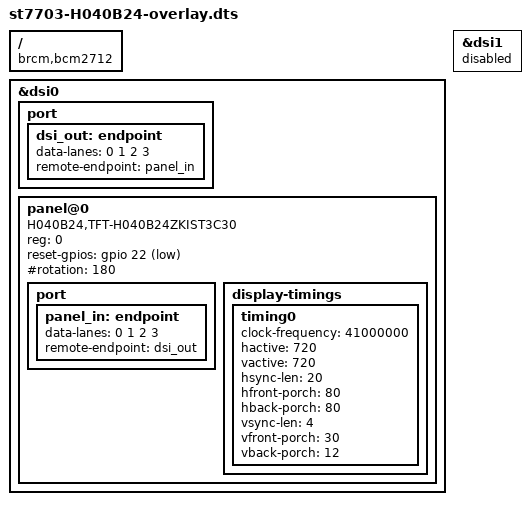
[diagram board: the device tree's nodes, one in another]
/dts-v1/;
/plugin/;

/ {
    compatible = "brcm,bcm2712";
};

&dsi0 {
    status = "okay";
    #address-cells = <1>;
    #size-cells = <0>;

    port {
        dsi_out: endpoint {
            data-lanes = <0 1 2 3>;
            remote-endpoint = <&panel_in>;
        };
    };

    panel@0 {
        compatible = "H040B24,TFT-H040B24ZKIST3C30";
        reg = <0>;
        reset-gpios = <&gpio 22 1>;  /* Active low reset - using GPIO 22 */
        
        /* Power supplies - these will be handled by regulators if available */
        /* vcc-supply = <&vcc_3v3>; */
        /* iovcc-supply = <&vcc_3v3>; */

        /* Rotate display 180 degrees */
        #rotation = <180>;

        port {
            panel_in: endpoint {
                data-lanes = <0 1 2 3>;
                remote-endpoint = <&dsi_out>;
            };
        };

        display-timings {
            timing0 {
                clock-frequency = <41000000>;  /* 41MHz */
                hactive = <720>;
                vactive = <720>;
                hsync-len = <20>;   /* HSA */
                hfront-porch = <80>; /* HFP */
                hback-porch = <80>;  /* HBP */
                vsync-len = <4>;     /* VSA */
                vfront-porch = <30>; /* VFP */
                vback-porch = <12>;  /* VBP */
            };
        };
    };
};

&dsi1 {
    status = "disabled";
	};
